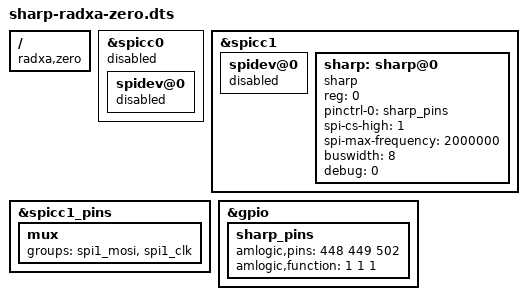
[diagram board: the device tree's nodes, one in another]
/dts-v1/;
/plugin/;

/ {
	compatible = "radxa,zero", "amlogic,g12a";


	fragment@0 {
		target = <&spicc0>;
		__overlay__ {
			status = "disabled";

			spidev@0{
				status = "disabled";
			};
        };
	};	


	fragment@1 {
		target = <&spicc1>;
		__overlay__ {
			status = "okay";

			spidev@0{
				status = "disabled";
			};
        };
	};	


	fragment@2 {
		target = <&spicc1_pins>;
		__overlay__ {
            mux {
                groups = "spi1_mosi",
                           "spi1_clk";
            };
        };
	};	

    fragment@3 {
		target = <&gpio>;
		__overlay__ {
			sharp_pins: sharp_pins {
                amlogic,pins = <448 449 502>;
				amlogic,function = <1 1 1>;	/* out */ 
			};
		};
	};

	fragment@4 {
		target = <&spicc1>;
		__overlay__ {
			/* needed to avoid dtc warning */
			#address-cells = <1>;
			#size-cells = <0>;

			sharp: sharp@0{
				compatible = "sharp";
				reg = <0>;
				pinctrl-names = "default";
				pinctrl-0 = <&sharp_pins>;
				spi-cs-high = <1>;
				spi-max-frequency = <2000000>;
				buswidth = <8>;
				debug = <0>;
			};

		};
	};
};
